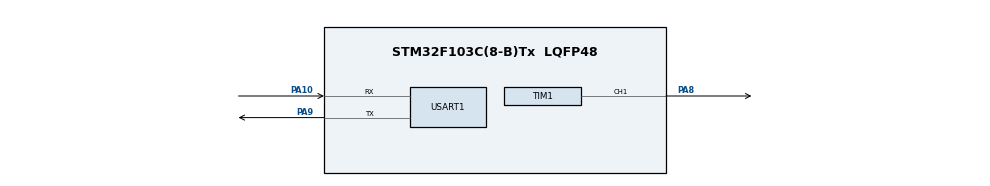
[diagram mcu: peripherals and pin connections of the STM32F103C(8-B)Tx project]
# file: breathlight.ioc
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Mcu.Family=STM32F1
Mcu.Name=STM32F103C(8-B)Tx
Mcu.Package=LQFP48
NVIC.PriorityGroup=NVIC_PRIORITYGROUP_4
NVIC.USART1_IRQn=true\:0\:0\:false\:false\:true\:true\:true\:true
PA10.Mode=Asynchronous
PA10.Signal=USART1_RX
PA13.Mode=Serial_Wire
PA13.Signal=SYS_JTMS-SWDIO
PA14.Mode=Serial_Wire
PA14.Signal=SYS_JTCK-SWCLK
PA8.Signal=S_TIM1_CH1
PA9.Mode=Asynchronous
PA9.Signal=USART1_TX
PD0-OSC_IN.Mode=HSE-External-Oscillator
PD0-OSC_IN.Signal=RCC_OSC_IN
PD1-OSC_OUT.Mode=HSE-External-Oscillator
PD1-OSC_OUT.Signal=RCC_OSC_OUT
ProjectManager.HeapSize=0x200
ProjectManager.StackSize=0x400
ProjectManager.TargetToolchain=STM32CubeIDE
RCC.APB1Freq_Value=8000000
RCC.APB2Freq_Value=8000000
SH.S_TIM1_CH1.0=TIM1_CH1,PWM Generation1 CH1
TIM1.AutoReloadPreload=TIM_AUTORELOAD_PRELOAD_ENABLE
TIM1.Channel-PWM\ Generation1\ CH1=TIM_CHANNEL_1
TIM1.Period=999
TIM1.Prescaler=7
USART1.VirtualMode=VM_ASYNC
VP_TIM1_VS_ClockSourceINT.Mode=Internal
board=custom

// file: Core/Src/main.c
/* USER CODE BEGIN Header */
/**
  ******************************************************************************
  * @file           : main.c
  * @brief          : Main program body
  ******************************************************************************
  * @attention
  *
  * Copyright (c) 2025 STMicroelectronics.
  * All rights reserved.
  *
  * This software is licensed under terms that can be found in the LICENSE file
  * in the root directory of this software component.
  * If no LICENSE file comes with this software, it is provided AS-IS.
  *
  ******************************************************************************
  */
/* USER CODE END Header */
#include "main.h"
#include "tim.h"
#include "usart.h"
#include "gpio.h"

/* USER CODE BEGIN Includes */
#include "math.h"
/* USER CODE END Includes */

void SystemClock_Config(void);
static uint8_t dataRcvd;
static uint8_t mode;

/* USER CODE BEGIN 0 */
void HAL_UART_RxCpltCallback(UART_HandleTypeDef *huart){
    if(huart==&huart1)
    {
        if(dataRcvd=='1')
        {
            mode=2;
        }
        else if(dataRcvd=='2')
        {
            mode=4;
        }
        else if(dataRcvd=='3')
        {
            mode=8;
        }

        HAL_UART_Receive_IT(&huart1,&dataRcvd,1);
    }
}
/* USER CODE END 0 */

int main(void)
{

  /* MCU Configuration--------------------------------------------------------*/

  /* Reset of all peripherals, Initializes the Flash interface and the Systick. */
  HAL_Init();

  /* Configure the system clock */
  SystemClock_Config();

  /* Initialize all configured peripherals */
  MX_GPIO_Init();
  MX_TIM1_Init();
  MX_USART1_UART_Init();
  /* USER CODE BEGIN 2 */
    HAL_TIM_PWM_Start(&htim1,TIM_CHANNEL_1);

  /* USER CODE END 2 */

  /* Infinite loop */
  /* USER CODE BEGIN WHILE */
    HAL_UART_Receive_IT(&huart1,&dataRcvd,1);
  while (1)
  {

      float t=HAL_GetTick()*0.001;

      float duty=0.5*sin(mode*3.14*t)+0.5;

      uint16_t arr= __HAL_TIM_GET_AUTORELOAD(&htim1);

      uint16_t ccr=duty*(arr+1);

      __HAL_TIM_SET_COMPARE(&htim1,TIM_CHANNEL_1,ccr);
    /* USER CODE END WHILE */

  }
}

void SystemClock_Config(void)
{
  RCC_OscInitTypeDef RCC_OscInitStruct = {0};
  RCC_ClkInitTypeDef RCC_ClkInitStruct = {0};

  /** Initializes the RCC Oscillators according to the specified parameters
  * in the RCC_OscInitTypeDef structure.
  */
  RCC_OscInitStruct.OscillatorType = RCC_OSCILLATORTYPE_HSI;
  RCC_OscInitStruct.HSIState = RCC_HSI_ON;
  RCC_OscInitStruct.HSICalibrationValue = RCC_HSICALIBRATION_DEFAULT;
  RCC_OscInitStruct.PLL.PLLState = RCC_PLL_NONE;
  if (HAL_RCC_OscConfig(&RCC_OscInitStruct) != HAL_OK)
  {
    Error_Handler();
  }

  /** Initializes the CPU, AHB and APB buses clocks
  */
  RCC_ClkInitStruct.ClockType = RCC_CLOCKTYPE_HCLK|RCC_CLOCKTYPE_SYSCLK
                              |RCC_CLOCKTYPE_PCLK1|RCC_CLOCKTYPE_PCLK2;
  RCC_ClkInitStruct.SYSCLKSource = RCC_SYSCLKSOURCE_HSI;
  RCC_ClkInitStruct.AHBCLKDivider = RCC_SYSCLK_DIV1;
  RCC_ClkInitStruct.APB1CLKDivider = RCC_HCLK_DIV1;
  RCC_ClkInitStruct.APB2CLKDivider = RCC_HCLK_DIV1;

  if (HAL_RCC_ClockConfig(&RCC_ClkInitStruct, FLASH_LATENCY_0) != HAL_OK)
  {
    Error_Handler();
  }
}

void Error_Handler(void)
{
  __disable_irq();
  while (1)
  {
  }
}
